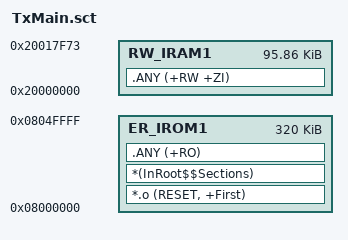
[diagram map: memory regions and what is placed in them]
; *************************************************************
; *** Scatter-Loading Description File generated by uVision ***
; *************************************************************

; Bank 1 Definition
LR_IROM1 0x08000000 (0x00080000)  {    ; load region size_region

  ER_IROM1 0x08000000 0x00050000 { ; code region
   *.o (RESET, +First)
   *(InRoot$$Sections)
   .ANY (+RO)
  }
  
  RW_IRAM1 0x20000000 (0x00018000-140) {  ; RW data
   .ANY (+RW +ZI)
  }
}
